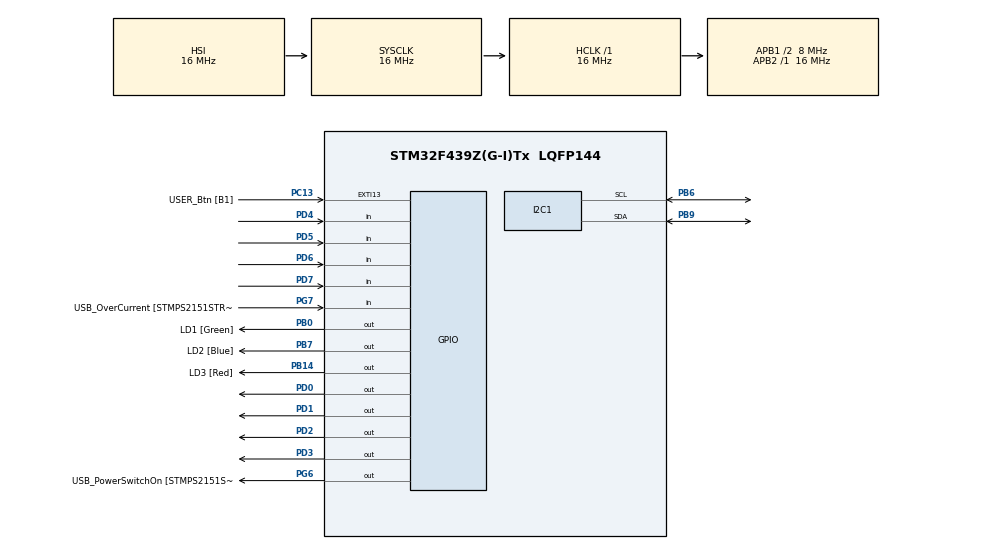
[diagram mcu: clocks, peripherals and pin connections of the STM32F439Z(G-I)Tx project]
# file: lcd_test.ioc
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Mcu.Family=STM32F4
Mcu.Name=STM32F439Z(G-I)Tx
Mcu.Package=LQFP144
NVIC.PriorityGroup=NVIC_PRIORITYGROUP_4
PA1.GPIO_Label=RMII_REF_CLK [LAN8742A-CZ-TR_REFCLK0]
PA1.Signal=ETH_REF_CLK
PA10.GPIO_Label=USB_ID
PA10.Signal=USB_OTG_FS_ID
PA11.GPIO_Label=USB_DM
PA11.Signal=USB_OTG_FS_DM
PA12.GPIO_Label=USB_DP
PA12.Signal=USB_OTG_FS_DP
PA13.GPIO_Label=TMS
PA13.Signal=SYS_JTMS-SWDIO
PA14.GPIO_Label=TCK
PA14.Signal=SYS_JTCK-SWCLK
PA2.GPIO_Label=RMII_MDIO [LAN8742A-CZ-TR_MDIO]
PA2.Signal=ETH_MDIO
PA7.GPIO_Label=RMII_CRS_DV [LAN8742A-CZ-TR_CRS_DV]
PA7.Signal=ETH_CRS_DV
PA8.GPIO_Label=USB_SOF [TP1]
PA8.Signal=USB_OTG_FS_SOF
PA9.GPIO_Label=USB_VBUS
PA9.Signal=USB_OTG_FS_VBUS
PB0.GPIO_Label=LD1 [Green]
PB0.Signal=GPIO_Output
PB13.GPIO_Label=RMII_TXD1 [LAN8742A-CZ-TR_TXD1]
PB13.Signal=ETH_TXD1
PB14.GPIO_Label=LD3 [Red]
PB14.Signal=GPIO_Output
PB6.Mode=I2C
PB6.Signal=I2C1_SCL
PB7.GPIO_Label=LD2 [Blue]
PB7.Signal=GPIO_Output
PB9.Mode=I2C
PB9.Signal=I2C1_SDA
PC1.GPIO_Label=RMII_MDC [LAN8742A-CZ-TR_MDC]
PC1.Signal=ETH_MDC
PC13.GPIO_Label=USER_Btn [B1]
PC13.Signal=GPXTI13
PC14/OSC32_IN.Signal=RCC_OSC32_IN
PC15/OSC32_OUT.Signal=RCC_OSC32_OUT
PC4.GPIO_Label=RMII_RXD0 [LAN8742A-CZ-TR_RXD0]
PC4.Signal=ETH_RXD0
PC5.GPIO_Label=RMII_RXD1 [LAN8742A-CZ-TR_RXD1]
PC5.Signal=ETH_RXD1
PD0.GPIO_PuPd=GPIO_NOPULL
PD0.Signal=GPIO_Output
PD1.GPIO_PuPd=GPIO_NOPULL
PD1.Signal=GPIO_Output
PD2.GPIO_PuPd=GPIO_NOPULL
PD2.Signal=GPIO_Output
PD3.GPIO_PuPd=GPIO_NOPULL
PD3.Signal=GPIO_Output
PD4.GPIO_PuPd=GPIO_PULLDOWN
PD4.Signal=GPIO_Input
PD5.GPIO_PuPd=GPIO_PULLDOWN
PD5.Signal=GPIO_Input
PD6.GPIO_PuPd=GPIO_PULLDOWN
PD6.Signal=GPIO_Input
PD7.GPIO_PuPd=GPIO_PULLDOWN
PD7.Signal=GPIO_Input
PD8.GPIO_Label=STLK_RX [STM32F103CBT6_PA3]
PD8.Signal=USART3_TX
PD9.GPIO_Label=STLK_TX [STM32F103CBT6_PA2]
PD9.Signal=USART3_RX
PG11.GPIO_Label=RMII_TX_EN [LAN8742A-CZ-TR_TXEN]
PG11.Signal=ETH_TX_EN
PG13.GPIO_Label=RMII_TXD0 [LAN8742A-CZ-TR_TXD0]
PG13.Signal=ETH_TXD0
PG6.GPIO_Label=USB_PowerSwitchOn [STMPS2151STR_EN]
PG6.Signal=GPIO_Output
PG7.GPIO_Label=USB_OverCurrent [STMPS2151STR_FAULT]
PG7.Signal=GPIO_Input
PH0/OSC_IN.GPIO_Label=MCO [STM32F103CBT6_PA8]
PH0/OSC_IN.Mode=HSE-External-Oscillator
PH0/OSC_IN.Signal=RCC_OSC_IN
PH1/OSC_OUT.Mode=HSE-External-Oscillator
PH1/OSC_OUT.Signal=RCC_OSC_OUT
ProjectManager.HeapSize=0x200
ProjectManager.StackSize=0x400
ProjectManager.TargetToolchain=STM32CubeIDE
RCC.48MHZClocksFreq_Value=48000000
RCC.AHBFreq_Value=16000000
RCC.APB1CLKDivider=RCC_HCLK_DIV2
RCC.APB1Freq_Value=8000000
RCC.APB1TimFreq_Value=16000000
RCC.APB2Freq_Value=16000000
RCC.APB2TimFreq_Value=16000000
RCC.CortexFreq_Value=16000000
RCC.HCLKFreq_Value=16000000
RCC.HSE_VALUE=8000000
RCC.HSI_VALUE=16000000
RCC.LSE_VALUE=32768
RCC.PLLMUL=RCC_PLL_MUL9
RCC.PRESCALERUSB=RCC_USBCLKSOURCE_PLL_DIV1_5
RCC.SYSCLKFreq_VALUE=16000000
RCC.SYSCLKSourceVirtual=RCC_SYSCLKSOURCE_PLLCLK
RCC.USBFreq_Value=48000000
RCC.VCOOutputFreq_Value=192000000
board=NUCLEO-F439ZI

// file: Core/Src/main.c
/* USER CODE BEGIN Header */
/**
 ******************************************************************************
 * @file           : main.c
 * @brief          : Main program body
 ******************************************************************************
 * @attention
 *
 * Copyright (c) 2023 STMicroelectronics.
 * All rights reserved.
 *
 * This software is licensed under terms that can be found in the LICENSE file
 * in the root directory of this software component.
 * If no LICENSE file comes with this software, it is provided AS-IS.
 *
 ******************************************************************************
 */
/* USER CODE END Header */
#include "main.h"
#include "i2c.h"
#include "gpio.h"

/* USER CODE BEGIN Includes */
#include "i2c.h"
#include "gpio.h"
#include "lcd.h"
#include "KEYPAD.h"
/* USER CODE END Includes */

/* USER CODE BEGIN PV */
//uint8_t gu8_KeyStatesArr[KEYS] = {0};
uint8_t SysTicks = 0;
/* USER CODE END PV */

void SystemClock_Config(void);
/* USER CODE BEGIN PFP */

//void SysTick_CallBack(void);
/* USER CODE END PFP */

/* USER CODE BEGIN 0 */

// Define global variable for backlight state

/* USER CODE END 0 */

int main(void)
{

  /* MCU Configuration--------------------------------------------------------*/

  /* Reset of all peripherals, Initializes the Flash interface and the Systick. */
  HAL_Init();

  /* Configure the system clock */
  SystemClock_Config();

  /* Initialize all configured peripherals */
  MX_GPIO_Init();
  MX_I2C1_Init();

  /* Infinite loop */
  /* USER CODE BEGIN WHILE */
	lcd_init();
	lcd_backlight(1); // Turn on backlight
    H_KeyPad_void_KeyPadInit();

	/*
	char *text = "OTA App";
	char *text2 = "FOTAAA";
	char *text3 = "FOTAAAAAAAAAAAAA";
	lcd_clear_line_up();
	lcd_write_string_up(text);
	HAL_Delay(2000);
	lcd_clear_line_up();
	lcd_write_string_up(text3);
	HAL_Delay(2000);

	lcd_write_string_down(text2);
	HAL_Delay(2000);
	lcd_clear_line_down();
	lcd_write_string_down(text3);
	HAL_Delay(2000);
	lcd_clear_line_up();
	lcd_write_int_up(55);
	HAL_Delay(2000);
	lcd_clear_line_down();
	lcd_write_int_down(77);
	HAL_Delay(2000);
	lcd_clear_line_up();
	lcd_clear_line_down();
*/

while (1)
  {
    /* USER CODE END WHILE */

    /* USER CODE BEGIN 3 */
	Keys_Detect();
	HAL_Delay(100);
  }
  /* USER CODE END 3 */
}

void SystemClock_Config(void)
{
  RCC_OscInitTypeDef RCC_OscInitStruct = {0};
  RCC_ClkInitTypeDef RCC_ClkInitStruct = {0};

  /** Configure the main internal regulator output voltage
  */
  __HAL_RCC_PWR_CLK_ENABLE();
  __HAL_PWR_VOLTAGESCALING_CONFIG(PWR_REGULATOR_VOLTAGE_SCALE3);

  /** Initializes the RCC Oscillators according to the specified parameters
  * in the RCC_OscInitTypeDef structure.
  */
  RCC_OscInitStruct.OscillatorType = RCC_OSCILLATORTYPE_HSI;
  RCC_OscInitStruct.HSIState = RCC_HSI_ON;
  RCC_OscInitStruct.HSICalibrationValue = RCC_HSICALIBRATION_DEFAULT;
  RCC_OscInitStruct.PLL.PLLState = RCC_PLL_NONE;
  if (HAL_RCC_OscConfig(&RCC_OscInitStruct) != HAL_OK)
  {
    Error_Handler();
  }

  /** Initializes the CPU, AHB and APB buses clocks
  */
  RCC_ClkInitStruct.ClockType = RCC_CLOCKTYPE_HCLK|RCC_CLOCKTYPE_SYSCLK
                              |RCC_CLOCKTYPE_PCLK1|RCC_CLOCKTYPE_PCLK2;
  RCC_ClkInitStruct.SYSCLKSource = RCC_SYSCLKSOURCE_HSI;
  RCC_ClkInitStruct.AHBCLKDivider = RCC_SYSCLK_DIV1;
  RCC_ClkInitStruct.APB1CLKDivider = RCC_HCLK_DIV2;
  RCC_ClkInitStruct.APB2CLKDivider = RCC_HCLK_DIV1;

  if (HAL_RCC_ClockConfig(&RCC_ClkInitStruct, FLASH_LATENCY_0) != HAL_OK)
  {
    Error_Handler();
  }
}

void Error_Handler(void)
{
	__disable_irq();
	while (1)
	{
	}
}
